# AT32UC3C0512C device description
Architecture: AVR32_UC3; Family: AVR UC3
Registers are 32-bit, read-write, reset 0x0 unless marked. A register's access mark holds for its fields unless they carry their own. Offsets are from the block's base; [hi:lo] are bit positions; lines under a group give offsets from that group; {n}, {i} and the like mark numbered series; 'fields as' and 'values as' point back to an identical list.

## SMC — Static Memory Controller
Instances: SMC 0xfffe2800
{0x0+0x10*i} cs[{i}] (i=0..5) group
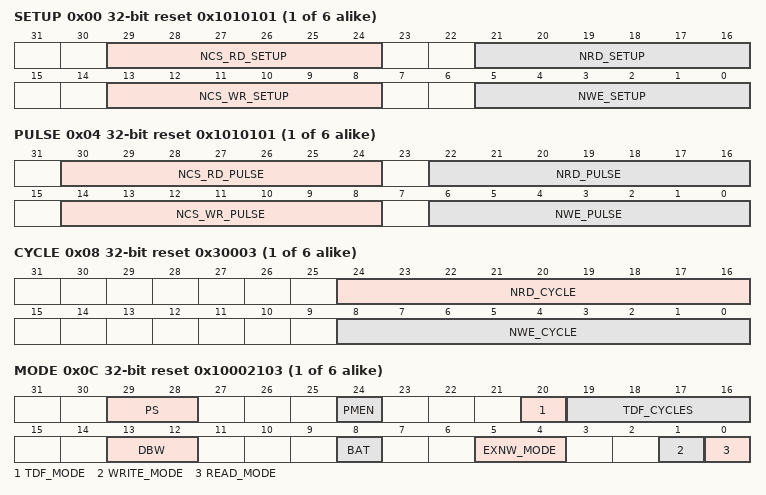
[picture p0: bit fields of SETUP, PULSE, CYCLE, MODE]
  0x00 SETUP reset 0x1010101 — SMC Setup Register
    [29:24] NCS_RD_SETUP — ncs setup length in READ access
    [21:16] NRD_SETUP — nrd setup length
    [13:8] NCS_WR_SETUP — ncs setup length in WRITE access
    [5:0] NWE_SETUP — nwe setup length
  0x04 PULSE reset 0x1010101 — SMC Pulse Register
    [30:24] NCS_RD_PULSE — ncs pulse length in READ access
    [22:16] NRD_PULSE — nrd pulse length
    [14:8] NCS_WR_PULSE — ncs pulse length in WRITE access
    [6:0] NWE_PULSE — nwe pulse length
  0x08 CYCLE reset 0x30003 — SMC Cycle Register
    [24:16] NRD_CYCLE — total read cycle length
    [8:0] NWE_CYCLE — total write cycle length
  0x0C MODE reset 0x10002103 — SMC Mode Register
    [29:28] PS — Page Size
    [24] PMEN — Page Mode enabled
    [20] TDF_MODE — TDF optimisation
    [19:16] TDF_CYCLES — Data Float Time
    [13:12] DBW — Data Bus Width
      0=8_BITS; 1=16_BITS; 2=32_BITS
    [8] BAT — Byte Access Type
      0=BYTE_SELECT; 1=BYTE_WRITE
    [5:4] EXNW_MODE — External Wait Mode
      0=DISABLED; 2=FROZEN; 3=READY
    [1] WRITE_MODE
      0=NCS_CONTROLLED; 1=NWE_CONTROLLED
    [0] READ_MODE
      0=NCS_CONTROLLED; 1=NRD_CONTROLLED
0xEC ADDRSIZE ro reset not defined — SMC Adress Size Register
0xF0 NAME1 ro reset not defined — SMC Name1 Register
0xF4 NAME2 ro reset not defined — SMC Name2 Register
0xF8 FEATURES ro reset not defined — SMC Features Register
0xFC VERSION ro reset not defined — SMC Version Register

## TWIM — Two-wire Master Interface
Instances: TWIM0 0xffff3800, TWIM1 0xffff3c00, TWIM2 0xfffd2c00
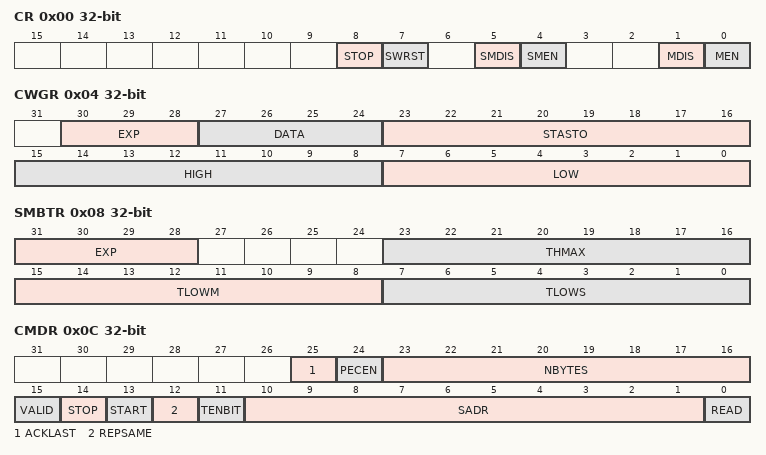
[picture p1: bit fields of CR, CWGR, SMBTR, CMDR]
0x00 CR wo — Control
  [8] STOP — Stop the current transfer
  [7] SWRST — Software Reset
  [5] SMDIS — SMBus Disable
  [4] SMEN — SMBus Enable
  [1] MDIS — Master Disable
  [0] MEN — Master Enable
0x04 CWGR — Clock Waveform Generator
  [30:28] EXP — Clock Prescaler
  [27:24] DATA — Data Setup and Hold Cycles
  [23:16] STASTO — START and STOP Cycles
  [15:8] HIGH — Clock High Cycles
  [7:0] LOW — Clock Low Cycles
0x08 SMBTR — SMBus Timing
  [31:28] EXP — SMBus Timeout Clock prescaler
  [23:16] THMAX — Clock High maximum cycles
  [15:8] TLOWM — Master Clock stretch maximum cycles
  [7:0] TLOWS — Slave Clock stretch maximum cycles
0x0C CMDR — Command
  [25] ACKLAST — ACK Last Master RX Byte
  [24] PECEN — Packet Error Checking Enable
  [23:16] NBYTES — Number of data bytes in transfer
  [15] VALID — CMDR Valid
  [14] STOP — Send STOP condition
  [13] START — Send START condition
  [12] REPSAME — Transfer is to same address as previous address
  [11] TENBIT — Ten Bit Addressing Mode
  [10:1] SADR — Slave Address
  [0] READ — Transfer Direction
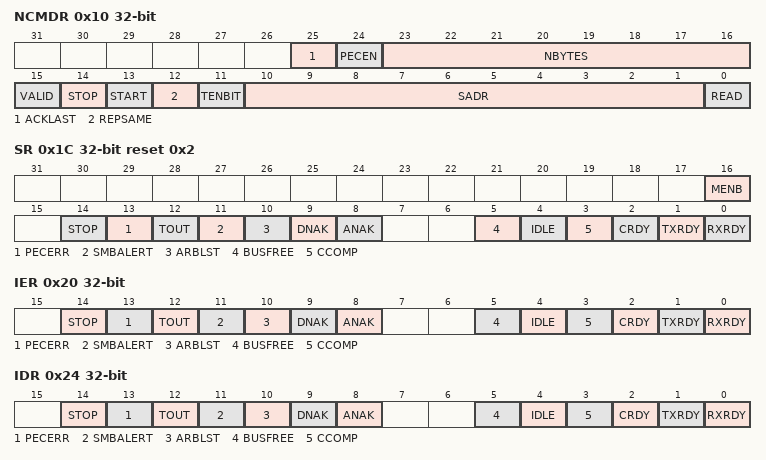
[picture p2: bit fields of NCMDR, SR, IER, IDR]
0x10 NCMDR — Next Command
  fields as CMDR
0x14 RHR ro — Receive Holding
  [7:0] RXDATA — Received Data
0x18 THR wo — Transmit Holding
  [7:0] TXDATA — Data to Transmit
0x1C SR ro reset 0x2 — Status
  [16] MENB — Master Interface Enable
  [14] STOP — Stop Request Accepted
  [13] PECERR — PEC Error
  [12] TOUT — Timeout
  [11] SMBALERT — SMBus Alert
  [10] ARBLST — Arbitration Lost
  [9] DNAK — NAK in Data Phase Received
  [8] ANAK — NAK in Address Phase Received
  [5] BUSFREE — Two-wire Bus is Free
  [4] IDLE — Master Interface is Idle
  [3] CCOMP — Command Complete
  [2] CRDY — Ready for More Commands
  [1] TXRDY — THR Data Ready
  [0] RXRDY — RHR Data Ready
0x20 IER wo — Interrupt Enable Register
  [14] STOP — Stop Request Accepted
  [13] PECERR — PEC Error
  [12] TOUT — Timeout
  [11] SMBALERT — SMBus Alert
  [10] ARBLST — Arbitration Lost
  [9] DNAK — NAK in Data Phase Received
  [8] ANAK — NAK in Address Phase Received
  [5] BUSFREE — Two-wire Bus is Free
  [4] IDLE — Master Interface is Idle
  [3] CCOMP — Command Complete
  [2] CRDY — Ready for More Commands
  [1] TXRDY — THR Data Ready
  [0] RXRDY — RHR Data Ready
0x24 IDR wo — Interrupt Disable Register
  fields as IER
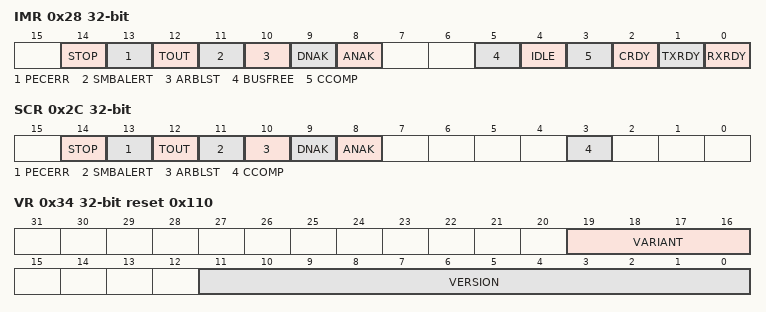
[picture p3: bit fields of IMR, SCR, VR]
0x28 IMR ro — Interrupt Mask Register
  fields as IER
0x2C SCR wo — Status Clear Register
  [14] STOP — Stop Request Accepted
  [13] PECERR — PEC Error
  [12] TOUT — Timeout
  [11] SMBALERT — SMBus Alert
  [10] ARBLST — Arbitration Lost
  [9] DNAK — NAK in Data Phase Received
  [8] ANAK — NAK in Address Phase Received
  [3] CCOMP — Command Complete
0x30 PR ro — Parameter Register
0x34 VR ro reset 0x110 — Version Register
  [19:16] VARIANT — Variant number
  [11:0] VERSION — Version number
